VERSION ""

NS_ :

BS_:

BU_:

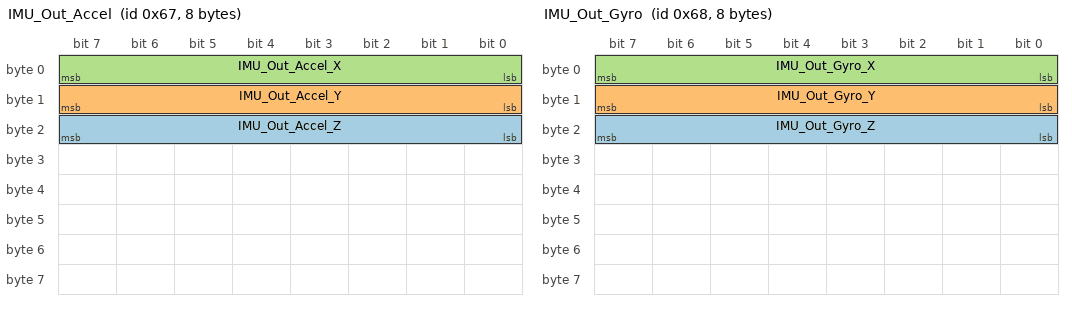
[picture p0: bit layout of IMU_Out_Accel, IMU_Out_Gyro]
BO_ 103 IMU_Out_Accel: 8 Vector__XXX
 SG_ IMU_Out_Accel_Z : 16|8@1- (0.0333333333333333,-4) [-4|4] "g" Vector__XXX
 SG_ IMU_Out_Accel_Y : 8|8@1- (0.0333333333333333,-4) [-4|4] "g" Vector__XXX
 SG_ IMU_Out_Accel_X : 0|8@1- (0.0333333333333333,-4) [-4|4] "g" Vector__XXX

BO_ 104 IMU_Out_Gyro: 8 Vector__XXX
 SG_ IMU_Out_Gyro_Z : 16|8@1- (2,-245) [-245|245] "rad/s" Vector__XXX
 SG_ IMU_Out_Gyro_Y : 8|8@1- (2,-245) [-245|245] "rad/s" Vector__XXX
 SG_ IMU_Out_Gyro_X : 0|8@1- (2,-245) [-245|245] "rad/s" Vector__XXX

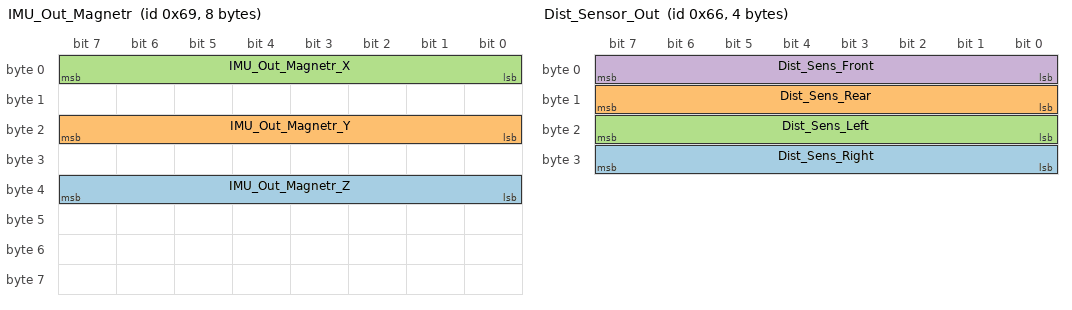
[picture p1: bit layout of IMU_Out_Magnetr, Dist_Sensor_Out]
BO_ 105 IMU_Out_Magnetr: 8 Vector__XXX
 SG_ IMU_Out_Magnetr_Z : 32|8@1- (0.01,-128) [-128|127] "uT" Vector__XXX
 SG_ IMU_Out_Magnetr_Y : 16|8@1- (0.01,-128) [-128|127] "uT" Vector__XXX
 SG_ IMU_Out_Magnetr_X : 0|8@1- (0.01,-128) [-128|127] "uT" Vector__XXX

BO_ 102 Dist_Sensor_Out: 4 Vector__XXX
 SG_ Dist_Sens_Right : 24|8@1+ (1,35) [40|290] "mm" Vector__XXX
 SG_ Dist_Sens_Rear : 8|8@1+ (1,35) [40|290] "mm" Vector__XXX
 SG_ Dist_Sens_Left : 16|8@1+ (1,35) [40|290] "mm" Vector__XXX
 SG_ Dist_Sens_Front : 0|8@1+ (1,35) [40|290] "mm" Vector__XXX

BO_ 101 Control_Signal: 2 Vector__XXX
 SG_ Steering_Value : 8|8@1- (1,-100) [0|200] "%" Vector__XXX
 SG_ Throttle_value : 0|8@1- (1,-100) [0|200] "%" Vector__XXX

CM_ SG_ 102 Dist_Sens_Right "0: Under 40mm
1: Over 290mm";
CM_ SG_ 102 Dist_Sens_Rear "0: Under 40mm
1: Over 290mm";
CM_ SG_ 102 Dist_Sens_Left "0: Under 40mm
1: Over 290mm";
CM_ SG_ 102 Dist_Sens_Front "0: Under 40mm
1: Over 290mm";
BA_DEF_  "BusType" STRING ;
BA_DEF_DEF_  "BusType" "CAN";
